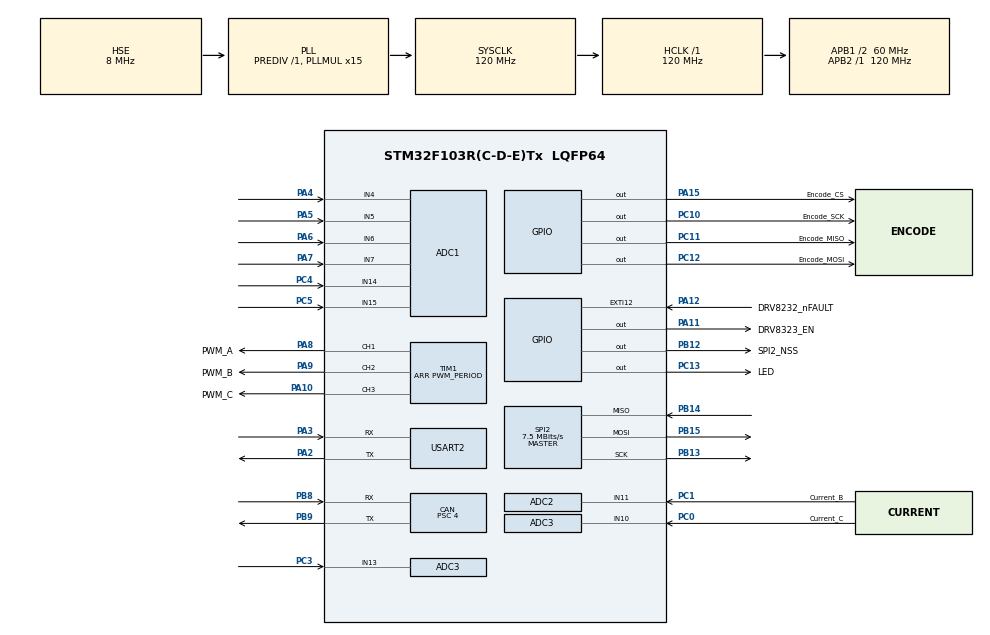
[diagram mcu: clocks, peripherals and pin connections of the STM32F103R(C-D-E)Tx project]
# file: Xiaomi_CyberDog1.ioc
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ADC1.Channel-1\#ChannelRegularConversion=ADC_CHANNEL_4
ADC1.Channel-3\#ChannelRegularConversion=ADC_CHANNEL_5
ADC1.Channel-4\#ChannelRegularConversion=ADC_CHANNEL_6
ADC1.Channel-5\#ChannelRegularConversion=ADC_CHANNEL_7
ADC1.Channel-6\#ChannelRegularConversion=ADC_CHANNEL_14
ADC1.Channel-7\#ChannelRegularConversion=ADC_CHANNEL_15
ADC1.ContinuousConvMode=DISABLE
ADC1.EnableInjectedConversion=DISABLE
ADC1.EnableRegularConversion=ENABLE
ADC1.ExternalTrigInjecConv=ADC_EXTERNALTRIGINJECCONV_T1_TRGO
ADC1.InjNumberOfConversion=1
ADC1.NbrOfConversion=6
ADC1.NbrOfConversionFlag=1
ADC1.Rank-1\#ChannelRegularConversion=1
ADC1.Rank-3\#ChannelRegularConversion=2
ADC1.Rank-4\#ChannelRegularConversion=3
ADC1.Rank-5\#ChannelRegularConversion=4
ADC1.Rank-6\#ChannelRegularConversion=5
ADC1.Rank-7\#ChannelRegularConversion=6
ADC1.SamplingTime-1\#ChannelRegularConversion=ADC_SAMPLETIME_28CYCLES_5
ADC1.SamplingTime-3\#ChannelRegularConversion=ADC_SAMPLETIME_28CYCLES_5
ADC1.SamplingTime-4\#ChannelRegularConversion=ADC_SAMPLETIME_28CYCLES_5
ADC1.SamplingTime-5\#ChannelRegularConversion=ADC_SAMPLETIME_28CYCLES_5
ADC1.SamplingTime-6\#ChannelRegularConversion=ADC_SAMPLETIME_28CYCLES_5
ADC1.SamplingTime-7\#ChannelRegularConversion=ADC_SAMPLETIME_28CYCLES_5
ADC1.master=1
ADC2.Channel-1\#ChannelInjectedConversion=ADC_CHANNEL_11
ADC2.ContinuousConvMode=ENABLE
ADC2.EnableInjectedConversion=ENABLE
ADC2.EnableRegularConversion=DISABLE
ADC2.ExternalTrigInjecConv=ADC_EXTERNALTRIGINJECCONV_T1_TRGO
ADC2.InjNumberOfConversion=1
ADC2.InjectedOffset-1\#ChannelInjectedConversion=0
ADC2.InjectedRank-1\#ChannelInjectedConversion=1
ADC2.SamplingTime-1\#ChannelInjectedConversion=ADC_SAMPLETIME_13CYCLES_5
ADC3.Channel-2\#ChannelRegularConversion=ADC_CHANNEL_13
ADC3.Channel-3\#ChannelInjectedConversion=ADC_CHANNEL_10
ADC3.Channel-4\#ChannelInjectedConversion=ADC_CHANNEL_13
ADC3.ContinuousConvMode=ENABLE
ADC3.EnableInjectedConversion=ENABLE
ADC3.ExternalTrigInjecConv=ADC_EXTERNALTRIGINJECCONV_T1_TRGO
ADC3.InjNumberOfConversion=2
ADC3.InjectedOffset-3\#ChannelInjectedConversion=0
ADC3.InjectedOffset-4\#ChannelInjectedConversion=0
ADC3.InjectedRank-3\#ChannelInjectedConversion=1
ADC3.InjectedRank-4\#ChannelInjectedConversion=2
ADC3.NbrOfConversionFlag=1
ADC3.Rank-2\#ChannelRegularConversion=1
ADC3.SamplingTime-2\#ChannelRegularConversion=ADC_SAMPLETIME_239CYCLES_5
ADC3.SamplingTime-3\#ChannelInjectedConversion=ADC_SAMPLETIME_13CYCLES_5
ADC3.SamplingTime-4\#ChannelInjectedConversion=ADC_SAMPLETIME_13CYCLES_5
CAN.ABOM=ENABLE
CAN.BS1=CAN_BS1_11TQ
CAN.BS2=CAN_BS2_3TQ
CAN.CalculateBaudRate=999999
CAN.CalculateTimeBit=1000
CAN.CalculateTimeQuantum=66.66666666666667
CAN.NART=ENABLE
CAN.Prescaler=4
CAN.TXFP=ENABLE
Dma.ADC1.0.Direction=DMA_PERIPH_TO_MEMORY
Dma.ADC1.0.Instance=DMA1_Channel1
Dma.ADC1.0.MemDataAlignment=DMA_MDATAALIGN_HALFWORD
Dma.ADC1.0.MemInc=DMA_MINC_ENABLE
Dma.ADC1.0.Mode=DMA_CIRCULAR
Dma.ADC1.0.PeriphDataAlignment=DMA_PDATAALIGN_HALFWORD
Dma.ADC1.0.PeriphInc=DMA_PINC_DISABLE
Dma.ADC1.0.Priority=DMA_PRIORITY_LOW
Dma.ADC3.3.Direction=DMA_PERIPH_TO_MEMORY
Dma.ADC3.3.Instance=DMA2_Channel5
Dma.ADC3.3.MemDataAlignment=DMA_MDATAALIGN_HALFWORD
Dma.ADC3.3.MemInc=DMA_MINC_ENABLE
Dma.ADC3.3.Mode=DMA_CIRCULAR
Dma.ADC3.3.PeriphDataAlignment=DMA_PDATAALIGN_HALFWORD
Dma.ADC3.3.PeriphInc=DMA_PINC_DISABLE
Dma.ADC3.3.Priority=DMA_PRIORITY_LOW
Dma.Request0=ADC1
Dma.Request1=SPI2_RX
Dma.Request2=SPI2_TX
Dma.Request3=ADC3
Dma.SPI2_RX.1.Direction=DMA_PERIPH_TO_MEMORY
Dma.SPI2_RX.1.Instance=DMA1_Channel4
Dma.SPI2_RX.1.MemDataAlignment=DMA_MDATAALIGN_BYTE
Dma.SPI2_RX.1.MemInc=DMA_MINC_ENABLE
Dma.SPI2_RX.1.Mode=DMA_NORMAL
Dma.SPI2_RX.1.PeriphDataAlignment=DMA_PDATAALIGN_BYTE
Dma.SPI2_RX.1.PeriphInc=DMA_PINC_DISABLE
Dma.SPI2_RX.1.Priority=DMA_PRIORITY_LOW
Dma.SPI2_TX.2.Direction=DMA_MEMORY_TO_PERIPH
Dma.SPI2_TX.2.Instance=DMA1_Channel5
Dma.SPI2_TX.2.MemDataAlignment=DMA_MDATAALIGN_BYTE
Dma.SPI2_TX.2.MemInc=DMA_MINC_ENABLE
Dma.SPI2_TX.2.Mode=DMA_NORMAL
Dma.SPI2_TX.2.PeriphDataAlignment=DMA_PDATAALIGN_BYTE
Dma.SPI2_TX.2.PeriphInc=DMA_PINC_DISABLE
Dma.SPI2_TX.2.Priority=DMA_PRIORITY_LOW
IWDG.Prescaler=IWDG_PRESCALER_32
IWDG.Reload=50
Mcu.Family=STM32F1
Mcu.Name=STM32F103R(C-D-E)Tx
Mcu.Package=LQFP64
Mcu.UserConstants=PWM_period,PWM_PERIOD;PWM_ADC_trgo,PWM_ADC_TRGO;wwdg_feed_interval_100us,WWDG_FEED_INTERVAL_100us
NVIC.ADC3_IRQn=true\:1\:0\:true\:false\:true\:true\:true\:true
NVIC.CAN1_SCE_IRQn=true\:6\:0\:true\:false\:true\:true\:true\:true
NVIC.DMA1_Channel4_IRQn=true\:2\:0\:true\:false\:true\:false\:true\:true
NVIC.DMA1_Channel5_IRQn=true\:2\:0\:true\:false\:true\:false\:true\:true
NVIC.EXTI15_10_IRQn=true\:0\:0\:false\:false\:true\:true\:true\:true
NVIC.PriorityGroup=NVIC_PRIORITYGROUP_4
NVIC.SPI2_IRQn=true\:2\:0\:true\:false\:true\:true\:true\:true
NVIC.TIM1_UP_IRQn=true\:1\:0\:true\:false\:true\:true\:true\:true
NVIC.TIM4_IRQn=true\:4\:0\:true\:false\:true\:true\:true\:true
NVIC.TIM6_IRQn=true\:15\:0\:false\:false\:true\:false\:true\:true
NVIC.TimeBase=TIM6_IRQn
NVIC.TimeBaseIP=TIM6
NVIC.USART2_IRQn=true\:7\:0\:true\:false\:true\:true\:true\:true
NVIC.USB_HP_CAN1_TX_IRQn=true\:6\:0\:true\:false\:true\:true\:true\:true
NVIC.USB_LP_CAN1_RX0_IRQn=true\:6\:0\:true\:false\:true\:true\:true\:true
PA10.GPIO_Label=PWM_C
PA10.Signal=S_TIM1_CH3
PA11.GPIO_Label=DRV8323_EN
PA11.Signal=GPIO_Output
PA12.GPIO_Label=DRV8232_nFAULT
PA12.GPIO_ModeDefaultEXTI=GPIO_MODE_IT_FALLING
PA12.GPIO_PuPd=GPIO_PULLUP
PA12.Signal=GPXTI12
PA13.Mode=Serial_Wire
PA13.Signal=SYS_JTMS-SWDIO
PA14.Mode=Serial_Wire
PA14.Signal=SYS_JTCK-SWCLK
PA15.GPIO_Label=Encode_CS
PA15.Signal=GPIO_Output
PA2.Mode=Asynchronous
PA2.Signal=USART2_TX
PA3.Mode=Asynchronous
PA3.Signal=USART2_RX
PA4.Signal=ADCx_IN4
PA5.Signal=ADCx_IN5
PA6.Signal=ADCx_IN6
PA7.Signal=ADCx_IN7
PA8.GPIO_Label=PWM_A
PA8.Signal=S_TIM1_CH1
PA9.GPIO_Label=PWM_B
PA9.Signal=S_TIM1_CH2
PB12.GPIO_Label=SPI2_NSS
PB12.GPIO_PuPd=GPIO_PULLUP
PB12.GPIO_Speed=GPIO_SPEED_FREQ_HIGH
PB12.PinState=GPIO_PIN_SET
PB12.Signal=GPIO_Output
PB13.Mode=Full_Duplex_Master
PB13.Signal=SPI2_SCK
PB14.Mode=Full_Duplex_Master
PB14.Signal=SPI2_MISO
PB15.Mode=Full_Duplex_Master
PB15.Signal=SPI2_MOSI
PB8.Mode=CAN_Activate
PB8.Signal=CAN_RX
PB9.Mode=CAN_Activate
PB9.Signal=CAN_TX
PC0.GPIO_Label=Current_C
PC0.Signal=ADCx_IN10
PC1.GPIO_Label=Current_B
PC1.Signal=ADCx_IN11
PC10.GPIO_Label=Encode_SCK
PC10.Signal=GPIO_Output
PC11.GPIO_Label=Encode_MISO
PC11.Signal=GPIO_Output
PC12.GPIO_Label=Encode_MOSI
PC12.Signal=GPIO_Output
PC13-TAMPER-RTC.GPIO_Label=LED
PC13-TAMPER-RTC.GPIO_PuPd=GPIO_PULLUP
PC13-TAMPER-RTC.Signal=GPIO_Output
PC3.Signal=ADCx_IN13
PC4.Signal=ADCx_IN14
PC5.Signal=ADCx_IN15
PD0-OSC_IN.Mode=HSE-External-Oscillator
PD0-OSC_IN.Signal=RCC_OSC_IN
PD1-OSC_OUT.Mode=HSE-External-Oscillator
PD1-OSC_OUT.Signal=RCC_OSC_OUT
ProjectManager.HeapSize=0x400
ProjectManager.StackSize=0x800
ProjectManager.TargetToolchain=CMake
RCC.ADCPresc=RCC_ADCPCLK2_DIV8
RCC.AHBFreq_Value=120000000
RCC.APB1CLKDivider=RCC_HCLK_DIV2
RCC.APB1Freq_Value=60000000
RCC.APB1TimFreq_Value=120000000
RCC.APB2Freq_Value=120000000
RCC.APB2TimFreq_Value=120000000
RCC.HCLKFreq_Value=120000000
RCC.PLLMUL=RCC_PLL_MUL15
RCC.PLLSourceVirtual=RCC_PLLSOURCE_HSE
RCC.SYSCLKFreq_VALUE=120000000
RCC.SYSCLKSource=RCC_SYSCLKSOURCE_PLLCLK
RCC.USBFreq_Value=120000000
SH.ADCx_IN10.0=ADC3_IN10,IN10
SH.ADCx_IN11.0=ADC2_IN11,IN11
SH.ADCx_IN13.0=ADC3_IN13,IN13
SH.ADCx_IN14.0=ADC1_IN14,IN14
SH.ADCx_IN15.0=ADC1_IN15,IN15
SH.ADCx_IN4.0=ADC1_IN4,IN4
SH.ADCx_IN5.0=ADC1_IN5,IN5
SH.ADCx_IN6.0=ADC1_IN6,IN6
SH.ADCx_IN7.0=ADC1_IN7,IN7
SH.S_TIM1_CH1.0=TIM1_CH1,PWM Generation1 CH1
SH.S_TIM1_CH2.0=TIM1_CH2,PWM Generation2 CH2
SH.S_TIM1_CH3.0=TIM1_CH3,PWM Generation3 CH3
SPI2.BaudRatePrescaler=SPI_BAUDRATEPRESCALER_8
SPI2.CLKPhase=SPI_PHASE_2EDGE
SPI2.CalculateBaudRate=7.5 MBits/s
SPI2.DataSize=SPI_DATASIZE_16BIT
SPI2.Direction=SPI_DIRECTION_2LINES
SPI2.Mode=SPI_MODE_MASTER
SPI2.VirtualType=VM_MASTER
TIM1.AutoReloadPreload=TIM_AUTORELOAD_PRELOAD_ENABLE
TIM1.BreakPolarity=TIM_BREAKPOLARITY_LOW
TIM1.BreakState=TIM_BREAK_DISABLE
TIM1.Channel-PWM\ Generation1\ CH1=TIM_CHANNEL_1
TIM1.Channel-PWM\ Generation2\ CH2=TIM_CHANNEL_2
TIM1.Channel-PWM\ Generation3\ CH3=TIM_CHANNEL_3
TIM1.Channel-PWM\ Generation4\ No\ Output=TIM_CHANNEL_4
TIM1.CounterMode=TIM_COUNTERMODE_CENTERALIGNED2
TIM1.Period=PWM_PERIOD
TIM1.Pulse-PWM\ Generation1\ CH1=PWM_PERIOD/2
TIM1.Pulse-PWM\ Generation2\ CH2=PWM_PERIOD/2
TIM1.Pulse-PWM\ Generation3\ CH3=PWM_PERIOD/2
TIM1.Pulse-PWM\ Generation4\ No\ Output=PWM_ADC_TRGO
TIM1.TIM_MasterOutputTrigger=TIM_TRGO_OC4REF
TIM4.Period=wwdg_feed_interval_100us - 1
TIM4.Prescaler=12000-1
USART2.VirtualMode=VM_ASYNC
VP_IWDG_VS_IWDG.Mode=IWDG_Activate
VP_SYS_VS_tim6.Mode=TIM6
VP_TIM1_VS_ClockSourceINT.Mode=Internal
VP_TIM1_VS_no_output4.Mode=PWM Generation4 No Output
VP_TIM4_VS_ClockSourceINT.Mode=Internal
board=custom

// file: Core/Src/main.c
/* USER CODE BEGIN Header */
/**
  ******************************************************************************
  * @file           : main.c
  * @brief          : Main program body
  ******************************************************************************
  * @attention
  *
  * Copyright (c) 2025 STMicroelectronics.
  * All rights reserved.
  *
  * This software is licensed under terms that can be found in the LICENSE file
  * in the root directory of this software component.
  * If no LICENSE file comes with this software, it is provided AS-IS.
  *
  ******************************************************************************
  */
/* USER CODE END Header */
#include "main.h"
#include "adc.h"
#include "can.h"
#include "dma.h"
#include "iwdg.h"
#include "spi.h"
#include "tim.h"
#include "usart.h"
#include "gpio.h"

/* USER CODE BEGIN Includes */
#include "main_user.h"
/* USER CODE END Includes */

void SystemClock_Config(void);

int main(void)
{

  /* USER CODE BEGIN 1 */
  /* GD32_PATCH: Enable FPU on Cortex-M4F (CP10 + CP11 full access).
     Equivalent to: (*(volatile uint32_t *)(0xE000ED88)) |= (15 << 20); */
  SCB->CPACR |= ((3UL << 20) | (3UL << 22));
  /* USER CODE END 1 */

  /* MCU Configuration--------------------------------------------------------*/

  /* Reset of all peripherals, Initializes the Flash interface and the Systick. */
  HAL_Init();

  /* Configure the system clock */
  SystemClock_Config();

  /* Initialize all configured peripherals */
  MX_GPIO_Init();
  MX_DMA_Init();
  MX_ADC1_Init();
  MX_ADC2_Init();
  MX_SPI2_Init();
  MX_TIM1_Init();
  MX_USART2_UART_Init();
  MX_IWDG_Init();
  MX_CAN_Init();
  MX_TIM4_Init();
  MX_ADC3_Init();
  /* USER CODE BEGIN 2 */

  main_user();

  /* USER CODE END 2 */

  /* Infinite loop */
  while (1)
  {

  }
}

void SystemClock_Config(void)
{
  RCC_OscInitTypeDef RCC_OscInitStruct = {0};
  RCC_ClkInitTypeDef RCC_ClkInitStruct = {0};
  RCC_PeriphCLKInitTypeDef PeriphClkInit = {0};

  /** Initializes the RCC Oscillators according to the specified parameters
  * in the RCC_OscInitTypeDef structure.
  */
  RCC_OscInitStruct.OscillatorType = RCC_OSCILLATORTYPE_LSI|RCC_OSCILLATORTYPE_HSE;
  RCC_OscInitStruct.HSEState = RCC_HSE_ON;
  RCC_OscInitStruct.HSEPredivValue = RCC_HSE_PREDIV_DIV1;
  RCC_OscInitStruct.HSIState = RCC_HSI_ON;
  RCC_OscInitStruct.LSIState = RCC_LSI_ON;
  RCC_OscInitStruct.PLL.PLLState = RCC_PLL_ON;
  RCC_OscInitStruct.PLL.PLLSource = RCC_PLLSOURCE_HSE;
  RCC_OscInitStruct.PLL.PLLMUL = RCC_PLL_MUL15;
  if (HAL_RCC_OscConfig(&RCC_OscInitStruct) != HAL_OK)
  {
    Error_Handler();
  }

  /** Initializes the CPU, AHB and APB buses clocks
  */
  RCC_ClkInitStruct.ClockType = RCC_CLOCKTYPE_HCLK|RCC_CLOCKTYPE_SYSCLK
                              |RCC_CLOCKTYPE_PCLK1|RCC_CLOCKTYPE_PCLK2;
  RCC_ClkInitStruct.SYSCLKSource = RCC_SYSCLKSOURCE_PLLCLK;
  RCC_ClkInitStruct.AHBCLKDivider = RCC_SYSCLK_DIV1;
  RCC_ClkInitStruct.APB1CLKDivider = RCC_HCLK_DIV2;
  RCC_ClkInitStruct.APB2CLKDivider = RCC_HCLK_DIV1;

  if (HAL_RCC_ClockConfig(&RCC_ClkInitStruct, FLASH_LATENCY_2) != HAL_OK)
  {
    Error_Handler();
  }
  PeriphClkInit.PeriphClockSelection = RCC_PERIPHCLK_ADC;
  PeriphClkInit.AdcClockSelection = RCC_ADCPCLK2_DIV8;
  if (HAL_RCCEx_PeriphCLKConfig(&PeriphClkInit) != HAL_OK)
  {
    Error_Handler();
  }
}

void HAL_TIM_PeriodElapsedCallback(TIM_HandleTypeDef *htim)
{
  if (htim->Instance == TIM6)
  {
    HAL_IncTick();
  }
  /* USER CODE BEGIN Callback 1 */
  /* ===== 调度器启动前的看门狗喂养点 =====
   * IWDG 在 MX_IWDG_Init() 里就已经启动（PSC=32/Reload=49 ≈ 40ms 超时），
   * 而 main_user() 的阻塞初始化最长一段是 Offset_Current_Start() 里的
   * HAL_Delay(300)，没有这个喂养点必然复位。
   *
   * TIM4 更新中断 5ms 一次（ARR 来自 Board_Config.h: WWDG_FEED_INTERVAL_100us=50，
   * 时钟 120MHz/PSC12000 = 100us/tick），NVIC 优先级 4（<5，所以这里绝不能调用
   * 任何 FreeRTOS API / printf）。启动与关闭都在 main_user() 里成对出现：
   * 调度器起来后必须关掉这个中断，否则"SafetyTask 卡死"会被 TIM4 掩盖。 */
  if (htim->Instance == TIM4)
  {
    HAL_IWDG_Refresh(&hiwdg);
  }
  /* USER CODE END Callback 1 */
}

void Error_Handler(void)
{
  __disable_irq();
  while (1)
  {
  }
}
